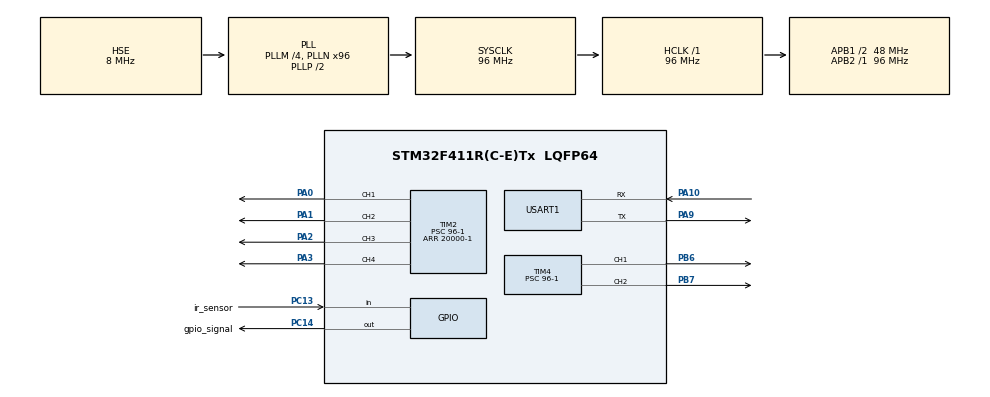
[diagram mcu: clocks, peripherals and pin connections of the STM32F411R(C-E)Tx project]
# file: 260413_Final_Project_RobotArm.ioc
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Mcu.Family=STM32F4
Mcu.Name=STM32F411R(C-E)Tx
Mcu.Package=LQFP64
NVIC.PriorityGroup=NVIC_PRIORITYGROUP_4
PA0-WKUP.Signal=S_TIM2_CH1_ETR
PA1.Signal=S_TIM2_CH2
PA10.Mode=Asynchronous
PA10.Signal=USART1_RX
PA2.Signal=S_TIM2_CH3
PA3.Signal=S_TIM2_CH4
PA9.Mode=Asynchronous
PA9.Signal=USART1_TX
PB6.Signal=S_TIM4_CH1
PB7.Signal=S_TIM4_CH2
PC13-ANTI_TAMP.GPIO_Label=ir_sensor
PC13-ANTI_TAMP.GPIO_PuPd=GPIO_PULLUP
PC13-ANTI_TAMP.Signal=GPIO_Input
PC14-OSC32_IN.GPIO_Label=gpio_signal
PC14-OSC32_IN.Signal=GPIO_Output
PH0\ -\ OSC_IN.Mode=HSE-External-Oscillator
PH0\ -\ OSC_IN.Signal=RCC_OSC_IN
PH1\ -\ OSC_OUT.Mode=HSE-External-Oscillator
PH1\ -\ OSC_OUT.Signal=RCC_OSC_OUT
ProjectManager.HeapSize=0x200
ProjectManager.StackSize=0x400
ProjectManager.TargetToolchain=STM32CubeIDE
RCC.48MHZClocksFreq_Value=48000000
RCC.AHBFreq_Value=96000000
RCC.APB1CLKDivider=RCC_HCLK_DIV2
RCC.APB1Freq_Value=48000000
RCC.APB1TimFreq_Value=96000000
RCC.APB2Freq_Value=96000000
RCC.APB2TimFreq_Value=96000000
RCC.CortexFreq_Value=96000000
RCC.HCLKFreq_Value=96000000
RCC.HSE_VALUE=8000000
RCC.HSI_VALUE=16000000
RCC.LSE_VALUE=32768
RCC.PLLM=4
RCC.PLLN=96
RCC.PLLSourceVirtual=RCC_PLLSOURCE_HSE
RCC.SYSCLKFreq_VALUE=96000000
RCC.SYSCLKSource=RCC_SYSCLKSOURCE_PLLCLK
RCC.VCOOutputFreq_Value=192000000
SH.S_TIM2_CH1_ETR.0=TIM2_CH1,PWM Generation1 CH1
SH.S_TIM2_CH2.0=TIM2_CH2,PWM Generation2 CH2
SH.S_TIM2_CH3.0=TIM2_CH3,PWM Generation3 CH3
SH.S_TIM2_CH4.0=TIM2_CH4,PWM Generation4 CH4
SH.S_TIM4_CH1.0=TIM4_CH1,PWM Generation1 CH1
SH.S_TIM4_CH2.0=TIM4_CH2,PWM Generation2 CH2
TIM2.Channel-PWM\ Generation1\ CH1=TIM_CHANNEL_1
TIM2.Channel-PWM\ Generation2\ CH2=TIM_CHANNEL_2
TIM2.Channel-PWM\ Generation3\ CH3=TIM_CHANNEL_3
TIM2.Channel-PWM\ Generation4\ CH4=TIM_CHANNEL_4
TIM2.Period=20000-1
TIM2.Prescaler=96-1
TIM2.Pulse-PWM\ Generation1\ CH1=1500
TIM2.Pulse-PWM\ Generation2\ CH2=1500
TIM2.Pulse-PWM\ Generation3\ CH3=1500
TIM2.Pulse-PWM\ Generation4\ CH4=1500
TIM4.Channel-PWM\ Generation1\ CH1=TIM_CHANNEL_1
TIM4.Channel-PWM\ Generation2\ CH2=TIM_CHANNEL_2
TIM4.Period=20000-1
TIM4.Prescaler=96-1
TIM4.Pulse-PWM\ Generation1\ CH1=1500
TIM4.Pulse-PWM\ Generation2\ CH2=1500
USART1.VirtualMode=VM_ASYNC
board=custom

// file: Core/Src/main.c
/* USER CODE BEGIN Header */
/**
 ******************************************************************************
 * @file           : main.c
 * @brief          : Main program body
 ******************************************************************************
 * @attention
 *
 * Copyright (c) 2026 STMicroelectronics.
 * All rights reserved.
 *
 * This software is licensed under terms that can be found in the LICENSE file
 * in the root directory of this software component.
 * If no LICENSE file comes with this software, it is provided AS-IS.
 *
 ******************************************************************************
 */
/* USER CODE END Header */
#include "main.h"

/* USER CODE BEGIN Includes */
#include "robot_arm.h"
#include "ir_sensor.h"
#include "gpio_signal.h"
#include "uart_com.h"
/* USER CODE END Includes */

TIM_HandleTypeDef htim2;
TIM_HandleTypeDef htim4;

UART_HandleTypeDef huart1;

void SystemClock_Config(void);
static void MX_GPIO_Init(void);
static void MX_TIM2_Init(void);
static void MX_TIM4_Init(void);
static void MX_USART1_UART_Init(void);

int main(void)
{

  /* MCU Configuration--------------------------------------------------------*/

  /* Reset of all peripherals, Initializes the Flash interface and the Systick. */
  HAL_Init();

  /* Configure the system clock */
  SystemClock_Config();

  /* Initialize all configured peripherals */
  MX_GPIO_Init();
  MX_TIM2_Init();
  MX_TIM4_Init();
  MX_USART1_UART_Init();
  /* USER CODE BEGIN 2 */
	IR_Sensor_Init();
	GPIO_Signal_Init();
	UART_Com_Init(&huart1);
	RobotArm_Init(&htim2, &htim4);
	UART_Com_SendStatus(ROBOT_STATUS_IDLE);
  /* USER CODE END 2 */

  /* Infinite loop */
	while (1) {
		if (IR_Sensor_IsDetected()) {
		        IR_Sensor_ClearFlag();
		        HAL_Delay(200);  // 디바운스
		        RobotArm_Run();
		    }
	}
}

void SystemClock_Config(void)
{
  RCC_OscInitTypeDef RCC_OscInitStruct = {0};
  RCC_ClkInitTypeDef RCC_ClkInitStruct = {0};

  /** Configure the main internal regulator output voltage
  */
  __HAL_RCC_PWR_CLK_ENABLE();
  __HAL_PWR_VOLTAGESCALING_CONFIG(PWR_REGULATOR_VOLTAGE_SCALE1);

  /** Initializes the RCC Oscillators according to the specified parameters
  * in the RCC_OscInitTypeDef structure.
  */
  RCC_OscInitStruct.OscillatorType = RCC_OSCILLATORTYPE_HSE;
  RCC_OscInitStruct.HSEState = RCC_HSE_ON;
  RCC_OscInitStruct.PLL.PLLState = RCC_PLL_ON;
  RCC_OscInitStruct.PLL.PLLSource = RCC_PLLSOURCE_HSE;
  RCC_OscInitStruct.PLL.PLLM = 4;
  RCC_OscInitStruct.PLL.PLLN = 96;
  RCC_OscInitStruct.PLL.PLLP = RCC_PLLP_DIV2;
  RCC_OscInitStruct.PLL.PLLQ = 4;
  if (HAL_RCC_OscConfig(&RCC_OscInitStruct) != HAL_OK)
  {
    Error_Handler();
  }

  /** Initializes the CPU, AHB and APB buses clocks
  */
  RCC_ClkInitStruct.ClockType = RCC_CLOCKTYPE_HCLK|RCC_CLOCKTYPE_SYSCLK
                              |RCC_CLOCKTYPE_PCLK1|RCC_CLOCKTYPE_PCLK2;
  RCC_ClkInitStruct.SYSCLKSource = RCC_SYSCLKSOURCE_PLLCLK;
  RCC_ClkInitStruct.AHBCLKDivider = RCC_SYSCLK_DIV1;
  RCC_ClkInitStruct.APB1CLKDivider = RCC_HCLK_DIV2;
  RCC_ClkInitStruct.APB2CLKDivider = RCC_HCLK_DIV1;

  if (HAL_RCC_ClockConfig(&RCC_ClkInitStruct, FLASH_LATENCY_3) != HAL_OK)
  {
    Error_Handler();
  }
}

static void MX_TIM2_Init(void)
{

  TIM_MasterConfigTypeDef sMasterConfig = {0};
  TIM_OC_InitTypeDef sConfigOC = {0};

  htim2.Instance = TIM2;
  htim2.Init.Prescaler = 96-1;
  htim2.Init.CounterMode = TIM_COUNTERMODE_UP;
  htim2.Init.Period = 20000-1;
  htim2.Init.ClockDivision = TIM_CLOCKDIVISION_DIV1;
  htim2.Init.AutoReloadPreload = TIM_AUTORELOAD_PRELOAD_DISABLE;
  if (HAL_TIM_PWM_Init(&htim2) != HAL_OK)
  {
    Error_Handler();
  }
  sMasterConfig.MasterOutputTrigger = TIM_TRGO_RESET;
  sMasterConfig.MasterSlaveMode = TIM_MASTERSLAVEMODE_DISABLE;
  if (HAL_TIMEx_MasterConfigSynchronization(&htim2, &sMasterConfig) != HAL_OK)
  {
    Error_Handler();
  }
  sConfigOC.OCMode = TIM_OCMODE_PWM1;
  sConfigOC.Pulse = 1500;
  sConfigOC.OCPolarity = TIM_OCPOLARITY_HIGH;
  sConfigOC.OCFastMode = TIM_OCFAST_DISABLE;
  if (HAL_TIM_PWM_ConfigChannel(&htim2, &sConfigOC, TIM_CHANNEL_1) != HAL_OK)
  {
    Error_Handler();
  }
  if (HAL_TIM_PWM_ConfigChannel(&htim2, &sConfigOC, TIM_CHANNEL_2) != HAL_OK)
  {
    Error_Handler();
  }
  if (HAL_TIM_PWM_ConfigChannel(&htim2, &sConfigOC, TIM_CHANNEL_3) != HAL_OK)
  {
    Error_Handler();
  }
  if (HAL_TIM_PWM_ConfigChannel(&htim2, &sConfigOC, TIM_CHANNEL_4) != HAL_OK)
  {
    Error_Handler();
  }
  HAL_TIM_MspPostInit(&htim2);

}

static void MX_TIM4_Init(void)
{

  TIM_MasterConfigTypeDef sMasterConfig = {0};
  TIM_OC_InitTypeDef sConfigOC = {0};

  htim4.Instance = TIM4;
  htim4.Init.Prescaler = 96-1;
  htim4.Init.CounterMode = TIM_COUNTERMODE_UP;
  htim4.Init.Period = 20000-1;
  htim4.Init.ClockDivision = TIM_CLOCKDIVISION_DIV1;
  htim4.Init.AutoReloadPreload = TIM_AUTORELOAD_PRELOAD_DISABLE;
  if (HAL_TIM_PWM_Init(&htim4) != HAL_OK)
  {
    Error_Handler();
  }
  sMasterConfig.MasterOutputTrigger = TIM_TRGO_RESET;
  sMasterConfig.MasterSlaveMode = TIM_MASTERSLAVEMODE_DISABLE;
  if (HAL_TIMEx_MasterConfigSynchronization(&htim4, &sMasterConfig) != HAL_OK)
  {
    Error_Handler();
  }
  sConfigOC.OCMode = TIM_OCMODE_PWM1;
  sConfigOC.Pulse = 1500;
  sConfigOC.OCPolarity = TIM_OCPOLARITY_HIGH;
  sConfigOC.OCFastMode = TIM_OCFAST_DISABLE;
  if (HAL_TIM_PWM_ConfigChannel(&htim4, &sConfigOC, TIM_CHANNEL_1) != HAL_OK)
  {
    Error_Handler();
  }
  if (HAL_TIM_PWM_ConfigChannel(&htim4, &sConfigOC, TIM_CHANNEL_2) != HAL_OK)
  {
    Error_Handler();
  }
  HAL_TIM_MspPostInit(&htim4);

}

static void MX_USART1_UART_Init(void)
{

  huart1.Instance = USART1;
  huart1.Init.BaudRate = 115200;
  huart1.Init.WordLength = UART_WORDLENGTH_8B;
  huart1.Init.StopBits = UART_STOPBITS_1;
  huart1.Init.Parity = UART_PARITY_NONE;
  huart1.Init.Mode = UART_MODE_TX_RX;
  huart1.Init.HwFlowCtl = UART_HWCONTROL_NONE;
  huart1.Init.OverSampling = UART_OVERSAMPLING_16;
  if (HAL_UART_Init(&huart1) != HAL_OK)
  {
    Error_Handler();
  }

}

static void MX_GPIO_Init(void)
{
  GPIO_InitTypeDef GPIO_InitStruct = {0};

  /* GPIO Ports Clock Enable */
  __HAL_RCC_GPIOC_CLK_ENABLE();
  __HAL_RCC_GPIOH_CLK_ENABLE();
  __HAL_RCC_GPIOA_CLK_ENABLE();
  __HAL_RCC_GPIOB_CLK_ENABLE();

  /*Configure GPIO pin Output Level */
  HAL_GPIO_WritePin(gpio_signal_GPIO_Port, gpio_signal_Pin, GPIO_PIN_RESET);

  /*Configure GPIO pin : ir_sensor_Pin */
  GPIO_InitStruct.Pin = ir_sensor_Pin;
  GPIO_InitStruct.Mode = GPIO_MODE_INPUT;
  GPIO_InitStruct.Pull = GPIO_PULLUP;
  HAL_GPIO_Init(ir_sensor_GPIO_Port, &GPIO_InitStruct);

  /*Configure GPIO pin : gpio_signal_Pin */
  GPIO_InitStruct.Pin = gpio_signal_Pin;
  GPIO_InitStruct.Mode = GPIO_MODE_OUTPUT_PP;
  GPIO_InitStruct.Pull = GPIO_NOPULL;
  GPIO_InitStruct.Speed = GPIO_SPEED_FREQ_LOW;
  HAL_GPIO_Init(gpio_signal_GPIO_Port, &GPIO_InitStruct);

}

void Error_Handler(void)
{
	__disable_irq();
	while (1) {
	}
}
